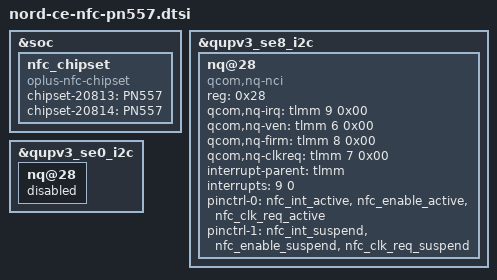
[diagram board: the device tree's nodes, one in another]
/**********************************************************************************
* Copyright (c)  2008-2022  Guangdong oplus Mobile Comm Corp., Ltd
* Description: oplus pn557 nfc dtsi
*
* Version: 1.0
* Date: 2022-03-10
* Author: huangtengming
*
* ------------------------------ Revision History: --------------------------------
* <version>           <date>                <author>                            <desc>
* Revision 1.0       2022-03-10            huangtengming           Created for  pn557 nfc dtsi
***********************************************************************************/
&soc {
	//add for nfc_chipset
	nfc_chipset {
		compatible = "oplus-nfc-chipset";
		chipset-20813 = "PN557";
		chipset-20814 = "PN557";
	};
};



&qupv3_se8_i2c {
	status = "ok";
	#address-cells = <1>;
	#size-cells = <0>;
	nq@28 {
		compatible = "qcom,nq-nci";
		reg = <0x28>;
		qcom,nq-irq = <&tlmm 9 0x00>;
		qcom,nq-ven = <&tlmm 6 0x00>;
		qcom,nq-firm = <&tlmm 8 0x00>;
		qcom,nq-clkreq = <&tlmm 7 0x00>;
		interrupt-parent = <&tlmm>;
		interrupts = <9 0>;
		interrupt-names = "nfc_irq";
		pinctrl-names = "nfc_active", "nfc_suspend";
		pinctrl-0 = <&nfc_int_active &nfc_enable_active
				&nfc_clk_req_active>;
		pinctrl-1 = <&nfc_int_suspend &nfc_enable_suspend
				&nfc_clk_req_suspend>;
	};
};

/* Ebba connects PN557 to SE8; remove the reference-board SE0 device. */
&qupv3_se0_i2c {
	nq@28 {
		status = "disabled";
	};
};

&qupv3_se8_i2c {
	/delete-node/ synaptics_tcm@20;
};
